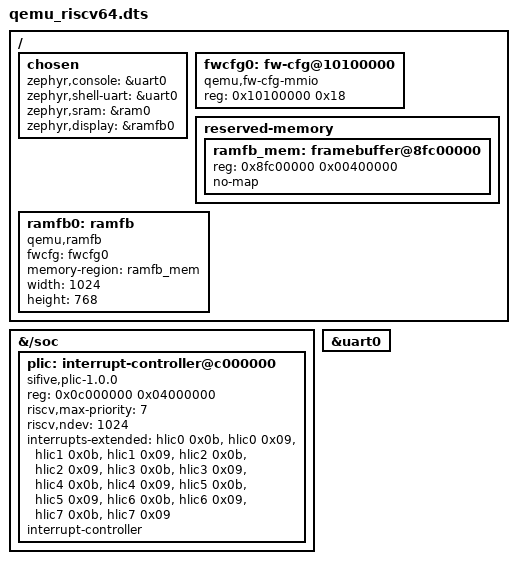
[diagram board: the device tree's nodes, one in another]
/* Copyright (c) 2019 BayLibre SAS */
/* SPDX-License-Identifier: Apache-2.0 */

/dts-v1/;

#include <qemu/virt-riscv64.dtsi>

/ {
	chosen {
		zephyr,console = &uart0;
		zephyr,shell-uart = &uart0;
		zephyr,sram = &ram0;
		zephyr,display = &ramfb0;
	};

	fwcfg0: fw-cfg@10100000 {
		compatible = "qemu,fw-cfg-mmio";
		reg = <0x10100000 0x18>;
		status = "okay";
	};

	reserved-memory {
		#address-cells = <1>;
		#size-cells = <1>;
		ranges;

		ramfb_mem: framebuffer@8fc00000 {
			reg = <0x8fc00000 0x00400000>; /* 4 MiB */
			no-map;
		};
	};

	ramfb0: ramfb {
		compatible = "qemu,ramfb";
		fwcfg = <&fwcfg0>;
		memory-region = <&ramfb_mem>;
		width = <1024>;
		height = <768>;
		status = "okay";
	};
};

&{/soc} {
	plic: interrupt-controller@c000000 {
		compatible = "sifive,plic-1.0.0";
		reg = <0x0c000000 0x04000000>;
		riscv,max-priority = <7>;
		riscv,ndev = <1024>;
		interrupts-extended = <&hlic0 0x0b &hlic0 0x09
				       &hlic1 0x0b &hlic1 0x09
				       &hlic2 0x0b &hlic2 0x09
				       &hlic3 0x0b &hlic3 0x09
				       &hlic4 0x0b &hlic4 0x09
				       &hlic5 0x0b &hlic5 0x09
				       &hlic6 0x0b &hlic6 0x09
				       &hlic7 0x0b &hlic7 0x09>;
		interrupt-controller;
		#address-cells = <0x00>;
		#interrupt-cells = <0x02>;
	};
};

&uart0 {
	status = "okay";
};
